# M55M1 register map
File version: 1.0
Registers are 32-bit, read-write, reset 0x0 unless marked. A register's access mark holds for its fields unless they carry their own. Offsets are from the block's base; [hi:lo] are bit positions; {n}, {i} and the like mark numbered series.

## I3Cn — I3C Register Map
Base 0x4029A000
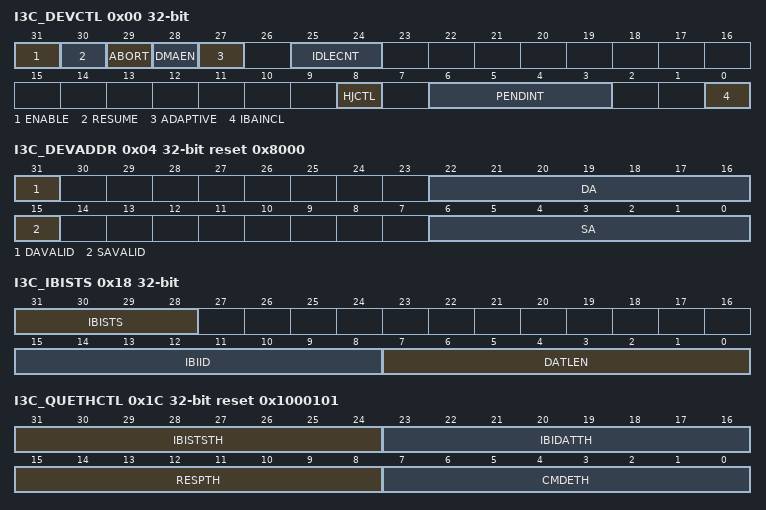
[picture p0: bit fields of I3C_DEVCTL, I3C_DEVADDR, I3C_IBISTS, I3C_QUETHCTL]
0x00 I3C_DEVCTL — I3C Device Control Register
  [31] ENABLE — Controls whether or not I3C is enabled. Note: 1.To Enable the Slave controller, the application must set the ENABLE bit to 1. Enabling the Slave controller might not be instantaneous because it is dependent on the availability of SCL clock on the I3C line. 2.To Disable the Slave controller, the application after setting the value of 0 to the ENABLE bit must keep polling the ENABLE bit to check whether the bit value is zero. Once the ENABLE bit is read with a value of zero, the application can be sure that the Slave controller is disabled. If the SCL clock is present, the Slave controller takes two SCL clocks to come out of the Disable state.
    0=I3C controller Disabled; 1=I3C controller Enabled
  [30] RESUME — I3C Resume Bit. This bit is used to resume the controller after it goes to the halt state. Note: This bit is cleared by writing 1 to it. In the Master mode of operation, the controller goes to the halt state due to any type of error in the transfer. After the controller gones to the halt state, the application has to write 1'b1 to this bit to resume the controller. This bit is auto-cleared once the controller resumes the transfers by initiating the next command. In the Slave mode of operation, the controller goes to the halt state due to following conditions: ■ Any type of error in the transfer ■ MRL Register updated by the master through SETMRL CCC. After the controller goes to the halt state, the application has to take necessary action to handle the error condition and then write 1'b1 to this bit to resume the controller. This bit is auto-cleared once the controller is ready to accept new transfers. (RESUME cannot auto-clear until GETSTATS CCC is received .if Slave has Protocol Error)
    0=RESUME operation is completion; 1=RESUME operation is in progress
  [29] ABORT — Abort Bit. This bit is used in Master mode of operation This bit allows the controller to relinquish the I3C bus before completing the issued transfer In response to an ABORT request, the controller issues the STOP condition after the complete data byte is transferred or received. This bit is auto-cleared once the transfer is aborted and the controller issues a 'Transfer Abort' interrupt.
  [28] DMAEN — DMA Handshake Interface Enable
    0=The DMA handshake control has no significance; 1=Enables the DMA handshake control to interact with external DMA
  [27] ADAPTIVE — Adaptive Mode (effect on HJ operation). This field is used in Slave mode of operation. Setting of this bit is NOT required to put the controller in Adaptive Mode. It is only used to enable some features of the Slave controller to adapt to Adaptive I2C/I3C mode of operation. This bit is cleared automatically if the controller determines the mode as I3C. Effect on Hot- Join: If this bit is programmed to 1'b1, the controller initiates a Hot-Join request only after it has switched to I3C mode of operation. If this bit is not set, the controller initiates a Hot- Join without determining the bus mode assuming itself to be on i3c bus. This bit should be set only if the Slave application does not know to which bus the device is connected to.
  [25:24] IDLECNT — Idle Count Multiplier. This bit is used in Slave mode of operation. After power-on reset, the Slave controller is enabled only after it sees both SDA and SCL lines idle for a specified time. This idle time is calculated by multiplying IDLE_ MUL with AVAILTC field in the I3C_BUSFAT register.
    0=Bus Avaliable time * 1; 1=Bus Avaliable time * 2; 2=Bus Avaliable time * 4; 3=Bus Avaliable time * 8
  [8] HJCTL — Hot-Join ACK/NACK Control. This bit is used in master mode of operation. This bit acts as a global control to ACK/NACK the Hot-Join request from the devices. The I3C Master ACK/NACKs the Hot-Join request from other devices connected on the I3C bus, based on programming of this bit.
    0=ACK the Hot-join request; 1=NACK and send broadcast CCC to disable Hot-Join
  [6:3] PENDINT — Pending Interrupt Status. This field is used in Slave mode of operation. This field is used for setting the interrupt number and is also reflected in I3C_CCCDEVS[3:0] PENDINT.
  [0] IBAINCL — I3C Broadcast Address include. This bit is used in Master mode of operation. This bit is used to include DWC_mipi_i3c broadcast address (0x7E) for private transfer. Note: If I3C broadcast address is not included for the private transfers, In-band Interrupts (IBI) driven from Slaves might not win address arbitration. Hence, the IBIs get delayed.
    0=I3C Broadcast Address is not included for Private Transfer; 1=I3C Broadcast Address is included for Private Transfers
0x04 I3C_DEVADDR reset 0x8000 — I3C Device Address Register
  [31] DAVALID — Dynamic Address Valid. In Master mode, the user sets this bit to 1 as it self-assigns its dynamic address. In I3C Slave Mode the Controller sets this bit to 1 when Main Master assigns the Dynamic address during ENTDAA or SETDASA mechanism. Note: This bit can be auto-clear to 0 if RSTDAA CCC is reveived.
    0=Dynamic Address is invalid; 1=Dynamic Address is valid
  [22:16] DA — Device Dynamic Address. In Master mode, the user/application has to program the Dynamic Address through the Slave interface as it self-assigns its Dynamic Address. In Slave mode, this field is used to indicate the device Dynamic Address after slave completes the dynamic address assignment operation by ENTDAA, SETDASA or SETNEDA CCC. Note: This field is read only.
  [15] SAVALID — Static Address Valid. In slave mode of operation this bit reflects the value of static_addr_en input port. The input port static_addr_en is expected to be driven to 1 only if the device supports I2C or I3C Static Address.
    0=Static Address is invalid; 1=Static Address is valid
  [6:0] SA — Device Static Address. The slave controller uses this address to respond to SETDASA CCC Command to get the Dynamic Address or performs Legacy I2C Read/Write operation.
0x0C I3C_CMDQUE wo — I3C Command Queue Port Register
  [31:0] CMDQUE — Command Queue. Please refer to chapter Master Command Data Structure and chapter Slave Command Data Structure
0x10 I3C_RESPQUE ro — I3C Response Queue Port Register
  [31:0] RESPQUE — Response Queue. Please refer to chapter Master Response Data Structure and chapter Slave Response Data Structure
0x14 I3C_TXRXDAT — I3C Transmit and Receive Data Port Register
  [31:0] DAT — Transmit and Receive Data Port. Transmit (Write) Operation: The Transmit Data port is mapped to the Tx-Data Buffer. The transmit data should always be packed as 4-byte aligned data words and written to the Transmit Data Port register. If the Command length is not aligned to 4-bytes, then the additional bytes are ignored. Receive (Read) Operation: The Receive Data port is mapped to the Rx-Data Buffer. The Receive data is always packed in 4-byte aligned data words and stored in the Rx-Data Buffer. If the command length is not aligned to the 4-bytes, then the additional data bytes have to be ignored.
0x18 I3C_IBIQUE ro — I3C In-Band Interrupt Queue Data Register
  [31:0] IBIDAT — In-Band Interrupt Data. This register is used in master mode of operation. This register when read from, reads the data from the IBI Queue. This register is mapped to the IBI Queue.The IBI Data is always packed in 4-byte aligned and put to the IBI Queue. If the incoming data is not aligned to the 4-bytes, then there are unused bytes in the end location of the IBI transfer
0x18 I3C_IBISTS ro (alternate view of I3C_IBIQUE) — I3C In-Band Interrupt Queue Status Register
  [31:28] IBISTS — I IBI Received Status. Defines the master response for IBI received. 4'b0xxx: Responded with ACK. 4'b1xxx: Responded with NACK. Others: RESERVED
  [15:8] IBIID — IBI Identifier. The byte received after START which includes the address and the R/W bit. Device address and R/W bit in case of Slave Interrupt or Master Request. Hot-Join ID and R/W bit in case of Hot-Join IBI.
  [7:0] DATLEN — In-Band Interrupt data length. This field represents the length of data received along with the IBI, in bytes.
0x1C I3C_QUETHCTL reset 0x1000101 — I3C Queue Threshold Control Register
  [31:24] IBISTSTH — In-Band Interrupt Status Threshold Value. Every In Band Interrupt received by I3C controller generates an IBI status. This field controls the number of IBI status entries (or greater) in the IBI queue that trigger the IBI_THLD_STAT interrupt. The valid range is 0 to IC_IBI_BUF_DEPTH-1. The software programs only valid values. A value of 0 sets the threshold for 1 entry, and a value of N sets the threshold for N+1 entries.
  [23:16] IBIDATTH — IBI Data Threshold Value. This field represents the IBI data segment size in Dwords (4 bytes). The minimum supported segment size is 1 (4 bytes) and the maximum supported size is IC_IBI_DATA_BUF_DEPTH-1. The IBI_DATA_THLD field enables the slicing of the incoming IBI data and generate individual status and thereby promotes the cut-through operation in reading out the IBI data.
  [15:8] RESPTH — Response Buffer Threshold Value. Controls the number of entries (or greater) in the Response. Queue that trigger the RESP_READY_STAT_INTR interrupt. The valid range is 0 to RESP_DT-1. The software programs only valid values. A value of 0 sets the threshold for 1 entry, and a value of N sets the threshold for N+1 entries.
  [7:0] CMDETH — Command Buffer Empty Threshold Value. Controls the number of empty locations (or greater) in the Command Queue that trigger CMD_QUEUE_READY_STAT interrupt. The valid range is 0 to CMD_BUF_DEPTH-1. The software programs only valid values. Value of N ranging from 1 to CMD_BUF_DEPTH-1 sets the threshold to N empty locations and a value of 0 sets the threshold to indicate that the queue is completely empty.
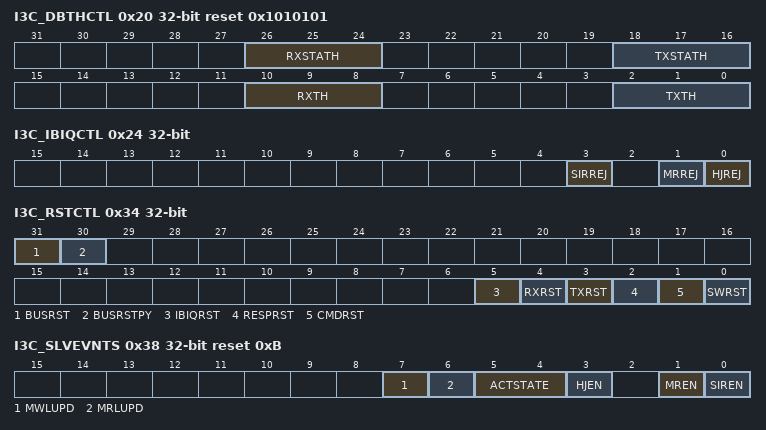
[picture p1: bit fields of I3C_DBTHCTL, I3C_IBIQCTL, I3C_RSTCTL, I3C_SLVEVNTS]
0x20 I3C_DBTHCTL reset 0x1010101 — I3C Data Buffer Threshold Control Register
  [all] fields
    0=1; 1=4; 2=8; 3=16; 4=32
  [26:24] RXSTATH — Receive Start Threshold Value. In master mode of operation when the controller is set up to initiate a read transfer, it waits until either one of the conditions are met before it initiates the read transfer on the I3C Interface. In the slave mode of operation the slave controller ACK's a write request from Master only if threshold number of empty locations(or more) are available in its receive buffer. The supported values for RXSTATH are:
  [18:16] TXSTATH — Transfer Start Threshold Value. In master mode of operation when the controller is set up to initiate a write transfer, it waits until either one of the following conditions are met before it initiates the write transfer on the I3C Interface. In slave mode of operation the slave controller ACK's a read request from Master only if either one of the following conditions are met: 1. Data length (as specified in the command) number of locations are filled in the Transmit FIFO. 2. Threshold number of entries (or more) are available in the Transmit FIFO. The supported values for RXSTATH are:
  [10:8] RXTH — Receive Buffer Threshold Value. The supported values for RXTH are
  [2:0] TXTH — Transmit Buffer Threshold Value. The supported values for TXTH are
0x24 I3C_IBIQCTL — I3C IBI Queue Control Register
  [3] SIRREJ — Notify Rejected Slave Interrupt Request Control. This bit is used to suppress reporting to the application about SIR request rejected. 0x0 : Notify SIR Rejected Disable. 0x1 : Notify SIR Rejected Enable. Note: This register is only used in master mode of operation
  [1] MRREJ — Notify Rejected Master Request Control. This bit is used to suppress reporting to the application about Master request rejected. 0x0 : Notify Master Request Rejected Disable. 0x1 : Notify Master Request Rejected Enable. Note: This register is only used in master mode of operation
  [0] HJREJ — Notify Rejected Master Request Control. This bit is used to suppress reporting to the application about Master request rejected. 0x0 : Notify Master Request Rejected Disable. 0x1 : Notify Master Request Rejected Enable. Note: This register is only used in master mode of operation
0x34 I3C_RSTCTL — I3C Reset Control Register
  [31] BUSRST — Bus Reset. This bit is only used in master mode of operation. Write 1'b1 to this bit to exercise Bus Reset Reset Pattern Generation based on Bus Reset Type selection. This bit is cleared automatically once the Bus Reset Pattern Generation is completed.
  [30] BUSRSTPY — Bus Reset type. Type of bus reset triggered by BUS_RESET field. 2'b00: EXIT: Exit Pattern. 2'b11: SCL_LOW_RESET Pattern
  [5] IBIQRST — IBI Queue Software Reset. This bit is only used in master mode of operation. Write 1'b1 to this bit to exercise IBI Queue reset This bit is cleared automatically once the IBI Queue reset is completed
  [4] RXRST — Receive Buffer Software Reset. Write 1'b1 to this bit to exercise Receive Buffer reset. This bit is cleared automatically once the Receive buffer reset is completed.
  [3] TXRST — Transmit Buffer Software Reset. Write 1'b1 to this bit to exercise Transmit Buffer reset. This bit is cleared automatically once the Transmit Buffer reset is completed.
  [2] RESPRST — Response Queue Software Reset. Write 1'b1 to this bit to exercise Response Queue reset. This bit is cleared automatically once the Response Queue reset is complete.
  [1] CMDRST — Command Queue Software Reset. Write 1'b1 to this bit to exercise Command Queue reset. This bit is cleared automatically once the Command Queue reset is complete.
  [0] SWRST — Core Software Reset. Write 1'b1 to this bit to exercise software reset. This resets all Buffers - Receive, Transmit, Command, and Response. This bit is cleared automatically once the core reset is complete.
0x38 I3C_SLVEVNTS reset 0xB — I3C Slave Event Status Register
  [7] MWLUPD — MWL Updated Status. This bit indicates a SETMWL CCC is received by the slave. The updated MWL value can be read from SLV_MAX_LEN register. This status can be cleared by writing 1'b1 to this field after reading the updated MWL. Note: This bit is cleared by writing 1 to it.
  [6] MRLUPD — MRL Updated Status. This bit indicates a SETMRL CCC is received by the slave. The updated MRL value can be read from SLV_MAX_LEN register. This status can be cleared by writing 1'b1 to this field after reading the updated MRL. Note: This bit is cleared by writing 1 to it.
  [5:4] ACTSTATE — Activity State Status. ENTAS0 - 00. ENTAS1 - 01. ENTAS2 - 10. ENTAS3 - 11. This bit reflects the Activity State of slave set by the Master. Note: This field is read only.
  [3] HJEN — Hot-Join Interrupt Enable Bit. This bit reflects whether the Hot-Join Request Interrupts are allowed on the I3C bus or not. The Slave application can choose to Disable HJ Capability of the SLave Controller (if selected) by setting this field to 0 before 'Enabling' the Controller. When done so, the Slave does not initiate Hot Join and takes part in Address Assignment without initiating Hot Join. If this field is NOT set to 0 by slave application, it can be set or cleared by the I3C Master through ENEC or DISEC CCCs. Once Disabled by software, CCCs do not have any effect on this field. Note: This field is read only.
  [1] MREN — Master Request Enable Bit. In Slave mode of operation, this bit reflects whether the controller can initiate the Master Request on the I3C bus or not.Usually, this bit is set or cleared by the I3C Master throughENEC or DISEC CCC. Note: This bit is read only.
  [0] SIREN — Slave Interrupt Request Enable Bit. In Slave mode of operation, this bit reflects whether the controller can initiate the SIR on the I3C bus or not. Usually, this bit is set or cleared by the I3C Master through ENEC or DISEC CCC. Note: This bit is read only.
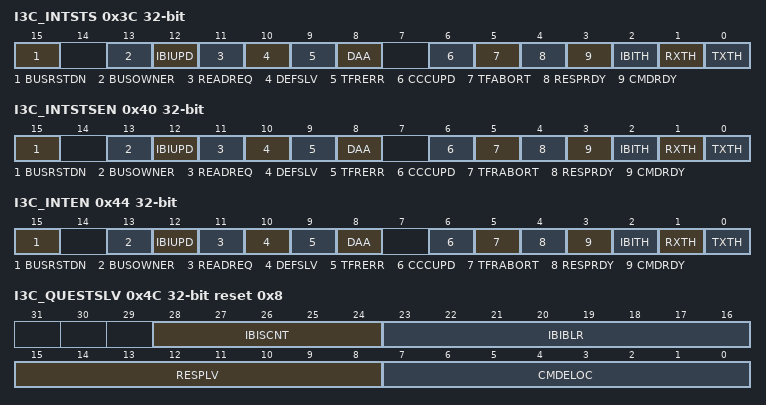
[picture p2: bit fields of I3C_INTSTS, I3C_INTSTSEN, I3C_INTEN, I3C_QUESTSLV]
0x3C I3C_INTSTS — I3C Interrupt Status Register
  [15] BUSRSTDN — Bus Reset Pattern Generation Done Status. This field is used only in Master mode of operation. This interrupt is generated when the SCL Low Timeout Bus Reset Pattern Generation is completed. This bit can be cleared by writing 1'b1.
  [13] BUSOWNER — Bus owner Updated Status. This interrupt is set when the role of the controller changes from being a Master to Slave or vice versa. This bit can be cleared by writing 1'b1.
  [12] IBIUPD — IBI Status Updated. This field is used only in slave mode of operation. It indicates that the IBI request initiated through SIR request register is addressed and status is updated. Note: This bit is cleared by writing 1 to it.
  [11] READREQ — Read Request Received. This field is used only in slave mode of operation. Read Request received from the current master when CMDQ is empty. This bit can be cleared by writing 1'b1. Note: This bit is cleared by writing 1 to it.
  [10] DEFSLV — Define Slave CCC Received Status. This interrupt is generated if DEFSLV CCC is received.This bit can be cleared by writing 1'b1.
  [9] TFRERR — Transfer Error Status. This interrupt is generated if any error occurs during transfer. The error type is specified in the response packet associated with the command (in ERR_STATUS field of RESPONSE_QUEUE_PORT register). This bit can be cleared by writing 1'b1. Note: This bit is cleared by writing 1 to it.
  [8] DAA — Dynamic Address Assigned Status. This field is used only in slave mode of operation. This interrupt is generated if the device's Dynamic Address is assigned through SETDASA or ENTDAA CCC. This bit can be cleared by writing 1'b1. Note: This bit is cleared by writing 1 to it.
  [6] CCCUPD — CCC Table Updated Status. This field is used only in slave mode of operation. This interrupt is generated if any of the CCC registers are updated by I3C Master through CCC commands. This interrupt can be cleared by writing 1'b1. Note: This bit is cleared by writing 1 to it.
  [5] TFABORT — Transfer Abort Status. This field is used only in master mode of operation. This interrupt is generated if transfer is aborted. This interrupt can be cleared by writing 1'b1.
  [4] RESPRDY — Response Queue Ready Status. This interrupt is generated when number of entries in response queue is greater than or equal to threshold value specified by RESPB_TD field in QUETHCTL register. This interrupt is cleared automatically when number of entries in response buffer is less than threshold value specified. Note: This bit is read only.
  [3] CMDRDY — Command Queue Ready Status. This interrupt is generated when number of empty locations in command queue is greater than or equal to threshold value specified by CMDEY_ TD field in QUETHCTL register. This interrupt is cleared automatically when number of empty locations in command buffer is less than threshold value specified. Note: This bit is read only.
  [2] IBITH — IBI Buffer Threshold Status. This field is only used in master mode of operation This interrupt is generated when number of entries in IBI buffer is greater than or equal to threshold value specified by IBISTTH field in I3C_QUETHCTL register. This interrupt is cleared automatically when number of entries in IBI buffer is less than threshold value specified.
  [1] RXTH — Receive Buffer Threshold Status. This interrupt is generated when number of entries in receive buffer is greater than or equal to threshold value specified by RXBUF_TD field in I3C_DBTHCTL register. This interrupt is cleared automatically when number of entries in receive buffer is less than threshold value specified. Note: This bit is read only.
  [0] TXTH — Transmit Buffer Threshold Status. This interrupt is generated when the number of empty locations in transmit buffer is greater than or equal to threshold value specified by TXBUF_TD field in I3C_DBTHCTL register. This interrupt is cleared automatically when number of empty locations in transmit buffer is less than threshold value specified. Note: This bit is read only.
0x40 I3C_INTSTSEN — I3C Interrupt Status Enable Register
  [15] BUSRSTDN — Bus Reset Pattern Generation Done Status Enable Bit. This field is used only in Master mode of operation.
  [13] BUSOWNER — Bus owner Updated Status Enable Bit
  [12] IBIUPD — IBI Updated Status Enable Bit. This field is used in slave mode of operation.
  [11] READREQ — Read Request Received Status Enable Bit. This field is used in slave mode of operation.
  [10] DEFSLV — Define Slave CCC Received Status Enable Bit
  [9] TFRERR — Transfer Error Status Enable Bit
  [8] DAA — Dynamic Address Assigned Status Enable Bit. This field is used in slave mode of operation.
  [6] CCCUPD — CCC Table Updated Status Enable Bit. This field is used in slave mode of operation.
  [5] TFRABORT — Transfer Abort Status Enable Bit. This field is used only in master mode of operation.
  [4] RESPRDY — Response Queue Ready Status Enable Bit
  [3] CMDRDY — Command Queue Ready Status Enable Bit
  [2] IBITH — IBI Buffer Threshold Status Enable Bit
  [1] RXTH — Receive Buffer Threshold Status Enable Bit
  [0] TXTH — Transmit Buffer Threshold Status Enable Bit
0x44 I3C_INTEN — I3C Interrupt Signal Enable Register
  [15] BUSRSTDN — Bus Reset Pattern Generation Done Signal Enable Bit. This field is used only in Master mode of operation.
  [13] BUSOWNER — Bus owner Updated Status Enable Bit
  [12] IBIUPD — IBI Updated Signal Enable Bit. This field is used in slave mode of operation.
  [11] READREQ — Read Request Received Signal Enable Bit. This field is used in slave mode of operation.
  [10] DEFSLV — Define Slave CCC Received Status Enable Bit
  [9] TFRERR — Transfer Error Signal Enable Bit
  [8] DAA — Dynamic Address Assigned Signal Enable Bit. This field is used in slave mode of operation.
  [6] CCCUPD — CCC Table Updated Signal Enable Bit. This field is used in slave mode of operation.
  [5] TFRABORT — Transfer Abort Status Signal Enable Bit. This field is used only in master mode of operation.
  [4] RESPRDY — Response Queue Ready Signal Enable Bit
  [3] CMDRDY — Command Queue Ready Signal Enable Bit
  [2] IBITH — IBI Buffer Threshold Signal Enable Bit
  [1] RXTH — Receive Buffer Threshold Signal Enable Bit
  [0] TXTH — Transmit Buffer Threshold Signal Enable Bit
0x4C I3C_QUESTSLV ro reset 0x8 — I3C Queue Status Level Register
  [28:24] IBISCNT — IBI Buffer Status Count. Contains the number of valid IBI Status entries in the IBI Status Buffer. This field is used in master mode of operation.
  [23:16] IBIBLR — IBI Buffer Level Value. Contains the number of valid IBI Data entries in the IBI Data Buffer. This field is used in master mode of operation
  [15:8] RESPLV — Response Buffer Level Value. Contains the number of valid data entries in the response Buffer.
  [7:0] CMDELOC — Command Queue Empty Locations. Contains the number of empty locations in the command Buffer.
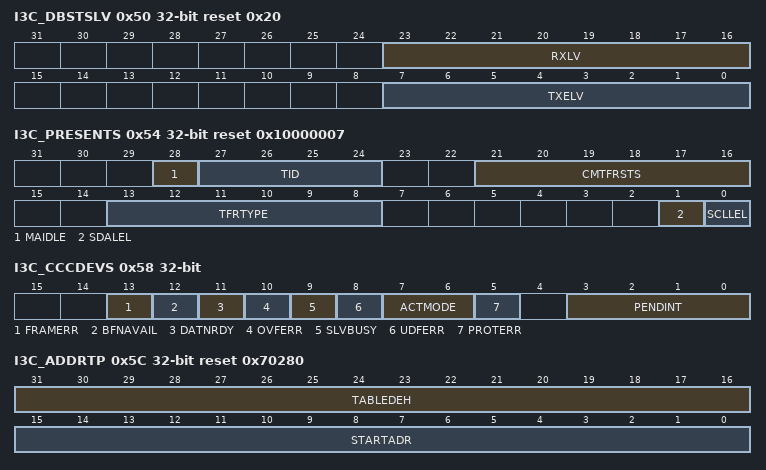
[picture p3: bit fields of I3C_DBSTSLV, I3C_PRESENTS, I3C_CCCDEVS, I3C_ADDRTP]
0x50 I3C_DBSTSLV ro reset 0x20 — I3C Data Buffer Status Level Register
  [23:16] RXLV — Receive Buffer Level Value. Contains the number of valid data entries in the receive Buffer.
  [7:0] TXELV — Transmit Buffer Empty Level Value. Contains the number of empty locations in the transmit Buffer.
0x54 I3C_PRESENTS ro reset 0x10000007 — I3C Present State Register
  [28] MAIDLE — This field reflects whether the Master Controller is in Idle state or not. This bit is set when all the Queues(Command , Response, IBI) and Buffers(Transmit and Receive) are empty along with the Master State machine is in Idle state. 0x0 (MST_NOT_IDLE): Master Controller is not in IDLE State. 0x1 (MST_IDLE): Master Controller is in IDLE State.
  [27:24] TID — Transmit Transaction ID. This field reflects the Transaction ID of the current executing command.
  [21:16] CMTFRSTS — Current Master Transfer State Status Indicates the state of current transfer currently executing by the I3C controller This is valid in Master mode only
  [13:8] TFRTYPE — Transfer Type Status. In Master mode of operation:
    0=IDLE (Controller is in Idle state); 1=Hot-Join transfer state; 2=IBI transfer state; 3=Master write transfer ongoing; 4=Read data prefetch state; 5=Master read transfer ongoing; 6=Slave controller in Halt State waiting for resume from application
  [1] SDALEL — This bit is used to check the SDA line level to recover from errors and for debugging. This bit reflects the value of synchronized sda input signal. This is valid in Master mode only.
  [0] SCLLEL — This bit is used to check the SCL line level to recover from errors and for debugging. This bit reflects the value of synchronized scl input signal. This is valid in Master mode only.
0x58 I3C_CCCDEVS ro — I3C Device Operating Status Register
  [13] FRAMERR — Frame Error. This bit is set when private write request from Master has frame error in HDR-DDR/HDR-TSP/TSL mode. This is cleared only after Master reads the device status through GETSTATUS_CCC.
  [12] BFNAVAIL — Buffer Not Available. This bit is set when private write request from Master is NACKED because of RX buffer not having RX_BUF_THLD number of empty locations or Response buffer is full. In SDR mode of operation this is cleared when the Master issues GET_STATUS CCC or upon space becoming available in the buffer and the successful completion of the next write transfer. In HDR mode of operation it is cleared only when Master issues GET_STATUS CCC
  [11] DATNRDY — Data Not Ready. This bit is set when private read request from Master is NACKED because of any of the following conditions. 1. Command FIFO Empty. 2. Transmit FIFO threshold is not met. 3. Response FIFO Full. This is cleared when the Master issues GET_STATUS CCC or upon successful completion of the subsequent read transfer.
  [10] OVFERR — Overflow Error. Overflow error condition detected during master write transfer. This is cleared only after master reads the Device Status through GETSTATUS CCC.
  [9] SLVBUSY — Slave Busy. This bit is set if any change is made by the current master in to MRL register or occurance of any error. It is cleared after slave application resumes the slave operation by writing 1'b1 in RESUME field of Device Control Register.
  [8] UDFERR — Underflow Error. Under Flow Error during private master read transfer. This bit is set if slave controller terminates a read transfer because of unavailability of data in the transmit buffer. This is cleared only after master reads the Device Status through GETSTATUS CCC.
  [7:6] ACTMODE — Activity Mode. This field reflects the input port signal act_mode.MIPI: Contains the two-bit ID of the Slave Device's current Activity Mode (readiness to support data read of sensor or related information).
  [5] PROTERR — Protocol Error. This bit is set when the slave controller encouters a Parity/CRC error during write data transfer.
  [3:0] PENDINT — Pending Interrupt. This field reflects the value driven on pending_int input port.
0x5C I3C_ADDRTP ro reset 0x70280 — I3C Pointer for Device Address Table Register
  [31:16] TABLEDEH — Depth of Device Address Table
  [15:0] STARTADR — Start Address of Device Address Table.
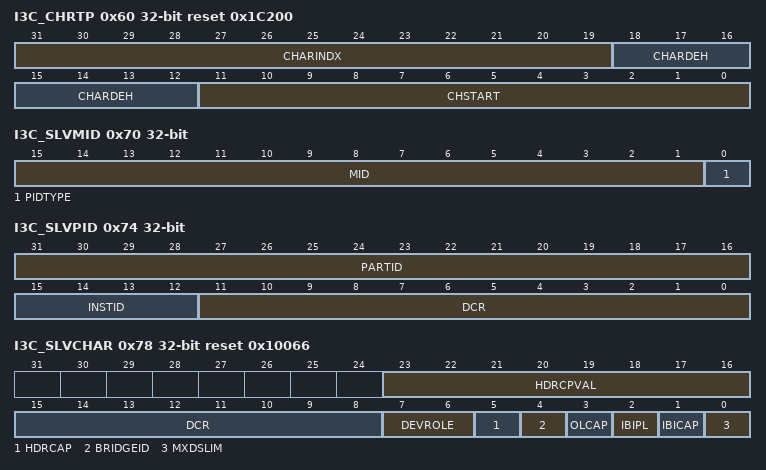
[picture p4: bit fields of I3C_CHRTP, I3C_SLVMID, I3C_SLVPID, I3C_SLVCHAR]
0x60 I3C_CHRTP ro reset 0x1C200 — I3C Pointer for Device Characteristics Table Register
  [31:19] CHARINDX — Current index of Device Characteristics Table This field returns the current location of Device Characteristics Table index Initially, this index points to 0 Once the complete characteristics information of a Slave device is written into Device Characteristics Table during ENTDAA, this index increments by 1 The first winning device information is stored in Device Characteristics Table index 0, the
  [18:12] CHARDEH — Depth of Device Characteristics Table
  [11:0] CHSTART — Start Address of Device Characteristics Table.
0x6C I3C_VENDOR ro reset 0xB0 — I3C Start Address of Vendor specific Register
  [15:0] VENODADR — Pointer for Vendor specific Registers
0x70 I3C_SLVMID — I3C MIPI Manufacturer ID Register
  [15:1] MID — Specifies the MIPI Manufacturer ID (PID[47:33]).
  [0] PIDTYPE — Specifies the Provisional ID Type Selector (PID[32]) (1'b1: Random Value, 1'b0: Vendor Fixed Value)
0x74 I3C_SLVPID — I3C Normal Provisional ID Register
  [31:16] PARTID — Specifies the Part ID of DWC_mipi_i3c device (PID[31:16])
  [15:12] INSTID — This field is used to program the instance ID of the Slave The reset value of this register is taken from input port 'inst_id'.
  [11:0] DCR — Specifies the additional 12-bit ID of DWC_mipi_i3c device (PID[11:0]).
0x78 I3C_SLVCHAR reset 0x10066 — I3C Slave Characteristic Register
  [23:16] HDRCPVAL — I3C Device HDR Capability Register Value. Note: This bit is read only.
    1=HDR-DDR
  [15:8] DCR — I3C Device Characteristic Value
  [7:6] DEVROLE — Device Role field in Bus Characteristic Register (BCR[7:6]). Note: This bit is read only.
  [5] HDRCAP — SDR Only or SDR and HDR Capable field in Bus Characteristic Register (BCR[5])
    0=SDR only. It doesn't disable the HW HDR feature, it just doesn't advertise the Slave HDR capability to Master; 1=HDR capable
  [4] BRIDGEID — Bridge Identifier field in Bus Characteristic Register (BCR[4]). Note: This bit is read only.
    0=Not a bridge device
  [3] OLCAP — Offline Capable field in Bus Characteristic Register (BCR[3]). Note: This bit is read only.
    0=Slave will always respond to I3C bus commands
  [2] IBIPL — IBI Payload field in Bus Characteristic Register (BCR[2]). Note: This bit is read only.
    1=Support IBI payload
  [1] IBICAP — IBI Request Capable field in Bus Characteristic Register (BCR[1]). Note: This bit is read only.
    1=Support IBI
  [0] MXDSLIM — Max Data Speed Limitation field in Bus Characteristic Register (BCR[0])
    0=No limitation; 1=Limitation
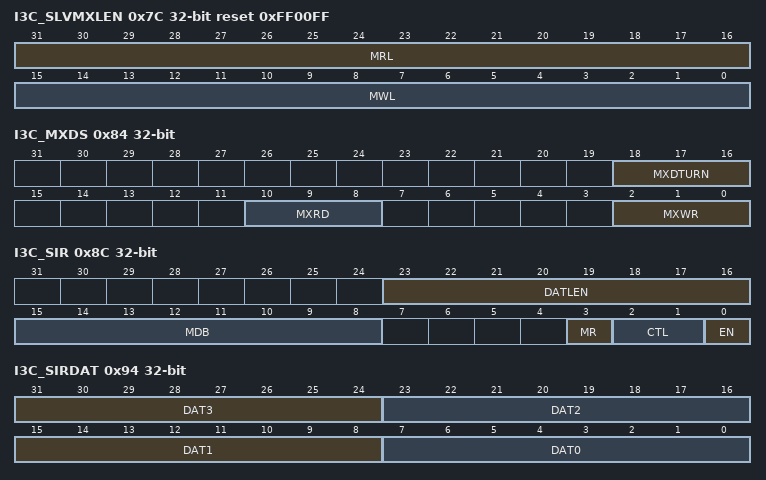
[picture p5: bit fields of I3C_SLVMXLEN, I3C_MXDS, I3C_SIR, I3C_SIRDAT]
0x7C I3C_SLVMXLEN ro reset 0xFF00FF — I3C Maximum Write/Read Length Register
  [31:16] MRL — I3C Device Max Read Length (Can be updated if SETMRL CCC is received)
  [15:0] MWL — I3C Device Max Write Length (Can be updated if SETMWL CCC is received)
0x80 I3C_MXRDTURN ro — I3C Maximum Read Turnaround Time Register
  [23:0] MXRDTURN — Specifies the maximum read turnaround time (in microseconds) (The 3rd byte which returned in the GETMXDS CCC). Note: This field is read only.
0x84 I3C_MXDS — I3C Maximum Data Speed Register
  [18:16] MXDTURN — Specifies the clock to data turnaround time (Tsco parameter)
    {v}={v+8} ns (v=0..4)
  [10:8] MXRD — Specifies the Maximum Sustained Data Rate for non-CCC messages sent by Slave Device to Master Device (The 2nd byte which returned in the GETMXDS CCC)
    0=12.5 MHz; 1=8 MHz; 2=6 MHz; 3=4 MHz; 4=2 MHz
  [2:0] MXWR — Specifies the Maximum Sustained Data Rate for non-CCC messages sent by Master Device to Slave device (The 1st byte which returned in the GETMXDS CCC)
    0=12.5 MHz; 1=8 MHz; 2=6 MHz; 3=4 MHz; 4=2 MHz
0x8C I3C_SIR — I3C Slave Interrupt Request Register
  [23:16] DATLEN — Slave Interrupt Request Data Length. This field should be programmed by the slave application to give the data length for the payload data other than the MDB byte. This field is only applicable when BCR[2] is set indicating that SIR supports payload data.
  [15:8] MDB — Mandatory Data Byte. This field gives the mandatory data byte which is required to be transmitted after the Master ACK the slave address during SIR transfer. This field is only applicable when BCR[2] is set indicating that SIR supports payload data.
  [3] MR — Master Request. When set, the controller attempts to issue the MR on the I3C bus. Once issued and when the current master accepts(ACK) or if the controller is unable to issue the MR, then the controller clears this bit automatically and updates the IBI_STS field. If NACK response is received for the MR, the controller reattempts the MR upon detecting the next START condition from the master or after the Bus Available time. This bit is available only in the secondary master configuration. For other configurations, this bit is reserved and returns 0 when read. Once set, the application cannot clear this bit.
  [2:1] CTL — Slave Interrupt Request Control
    0=Indicates source of SIR data to be from the registers
  [0] EN — Slave Interrupt Request. When set, the slave controller attempts to issue the SIR on the I3C bus. Once issued and when the current master accepts (ACK) or if the controller is unable to issue the SIR, then the controller clears this bit automatically and updates the IBI_STS field. If the NACK response is received for the SIR, the controller reattempts the SIR upon detecting the next START condition from the master or after the Bus Available Time. Once set, the application cannot clear this bit.
0x94 I3C_SIRDAT — I3C Slave Interrupt Request Data Register
  [31:24] DAT3 — SIR Data Byte 3. This register SIRDATA containing four bytes of SIR Data will be in effect only when SIR_CTRL field in INTRREQ is programmed to 00 provided the data length is up to 4. This field holds the fourth byte of SIR DATA that will be passed after the MDB when SIR is initiated by the application on writing into SIR bit in INTRREQ Register.
  [23:16] DAT2 — SIR Data Byte 2. This register SIRDATA containing four bytes of SIR Data will be in effect only when SIR_CTRL field in INTRREQ is programmed to 00 provided the data length is up to 3. This field holds the third byte of SIR DATA that will be passed after the MDB when SIR is initiated by the application on writing into SIR bit in INTRREQ Register.
  [15:8] DAT1 — SIR Data Byte 1. This register SIRDATA containing four bytes of SIR Data will be in effect only when SIR_CTRL field in INTRREQ is programmed to 00 provided the data length is up to 2. This field holds the second byte of SIR DATA that will be passed after the MDB when SIR is initiated by the application on writing into SIR bit in INTRREQ Register.
  [7:0] DAT0 — SIR Data Byte 0. This register SIRDATA containing four bytes of SIR Data will be in effect only when SIR_CTRL field in INTRREQ is programmed to 00 provided the data length is up to 1. This field holds the first byte of SIR DATA that will be passed after the MDB when SIR is initiated by the application on writing into SIR bit in INTRREQ Register.
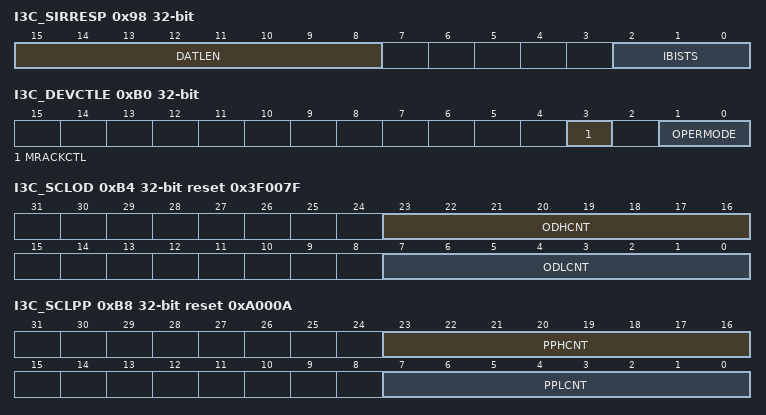
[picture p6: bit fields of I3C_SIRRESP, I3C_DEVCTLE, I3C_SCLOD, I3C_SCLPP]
0x98 I3C_SIRRESP — I3C Slave Interrupt Request Response Register
  [15:8] DATLEN — Data Length for SIR Response. The value in this filed will indicate the number of bytes remaining that was not transmitted because of Master early terminating the SIR transfer. In case the IBI is not attempted the number for bytes returned will be same as that programmed for IBI payload
  [2:0] IBISTS — IBI Completion Status. This field is common for SIR and MR. The controller does not attempt to issue the IBI and generates the IBI Completion Status as 3'b011 if one of the following condition is true. 1. Master has not assigned the Dynamic Address. 2. Master has cleared the assigned Dynamic Address (through RSTDAA CCC). 3. Master has disabled the IBI event (through DISEC CCC). 4. The controller has switched the role to Master (applicable only for secondary master configuration). 5. DL doesn't match with SIR_CTRL.
    1=IBI accepted by the Master (ACK response received); 2=Master Early Terminate (only for SIR with Data); 3=IBI Not Attempted
0xB0 I3C_DEVCTLE — I3C Device Control Extended Register
  [3] MRACKCTL — In Slave mode of operation, this bit serves as a control to ACK/NACK GETACCMST CCC from current master. 0: ACK GETACCMST CCC. 1: NACK GETACCMST CCC
  [1:0] OPERMODE — This bit is used to select the Device Operation Mode before the controller is enabled. 0: Master. 1: Slave. 2: Reserved. 3: Reserved. Note:This field is written only when the i3c is disabled
0xB4 I3C_SCLOD reset 0x3F007F — I3C SCL Open Drain Timing Register
  [23:16] ODHCNT — I3C Open Drain High Count. SCL open-drain High count for I3C transfers targeted to I3C devices. Note: ODHCNT minimum value is five
  [7:0] ODLCNT — I3C Open Drain Low Count. SCL Open-drain low count for I3C transfers targeted to I3C devices. Note: ODLCNT minimum value is five
0xB8 I3C_SCLPP reset 0xA000A — I3C SCL Push Pull Timing Register
  [23:16] PPHCNT — I3C Push Pull High Count. SCL Push-Pull High count for I3C transfers targeted to I3C devices. Note: PPHCNT minimum value is five
  [7:0] PPLCNT — I3C Push Pull Low Count. SCL Push-Pull low count for I3C transfers targeted to I3C devices. Note: PPLCNT minimum value is five
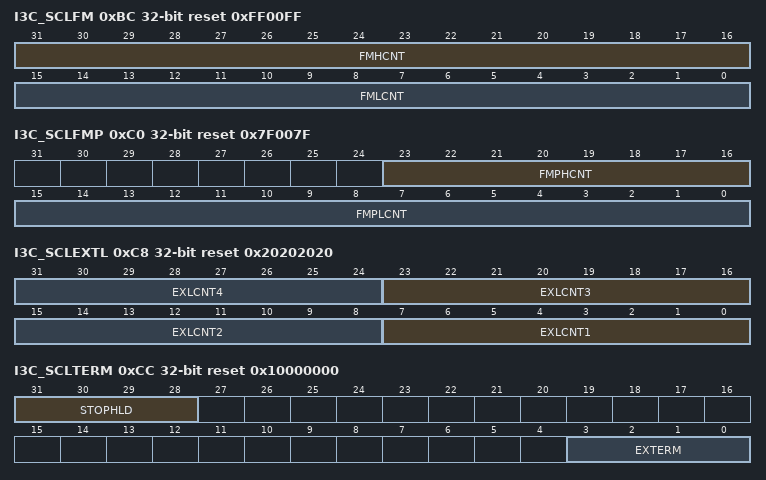
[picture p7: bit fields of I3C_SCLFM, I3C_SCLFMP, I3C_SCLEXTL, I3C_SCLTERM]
0xBC I3C_SCLFM reset 0xFF00FF — I3C SCL I2C Fast Mode Timing Register
  [31:16] FMHCNT — I2C Fast Mode High Count. The SCL open-drain high count timing for I2C fast mode transfers. Note: FMHCNT minimum value is five
  [15:0] FMLCNT — I2C Fast Mode Low Count. The SCL open-drain low count timing for I2C fast mode transfers. Note: FMLCNT minimum value is five
0xC0 I3C_SCLFMP reset 0x7F007F — I3C SCL I2C Fast Mode Plus Timing Register
  [23:16] FMPHCNT — I2C Fast Mode High Count. The SCL open-drain high count timing for I2C fast mode transfers. Note: FMPHCNT minimum value is five
  [15:0] FMPLCNT — I2C Fast Mode Low Count. The SCL open-drain low count timing for I2C fast mode transfers. Note: FMPLCNT minimum value is five
0xC8 I3C_SCLEXTL reset 0x20202020 — I3C SCL Extended Low Count Timing Register
  [8n-1:8n-8] EXLCNT{n} (n=1..4) — I3C Extended Low Count Register {n}. SDR{n} uses this register field for data transfer
0xCC I3C_SCLTERM reset 0x10000000 — I3C SCL Termination Bit Low count Timing Register
  [31:28] STOPHLD — STOP HOLD Count. Stop Hold Count in terms of ECLK which is used for generation of Stop Hold generation in Controller Mode.
  [3:0] EXTERM — I3C Read Termination Bit Low count. Extended I3C Read Termination Bit low count for I3C Readtransfers. Effective Termination-Bit Low Period is derived based on the SDR speed as shown below SDR0 speed: PPLCNT + EXTERM. SDR1 speed: EXLCNT1 + EXTERM. SDR2 speed: EXLCNT2 + EXTERM. SDR3 speed: EXLCNT3 + EXTERM. SDR4 speed: EXLCNT4 + EXTERM
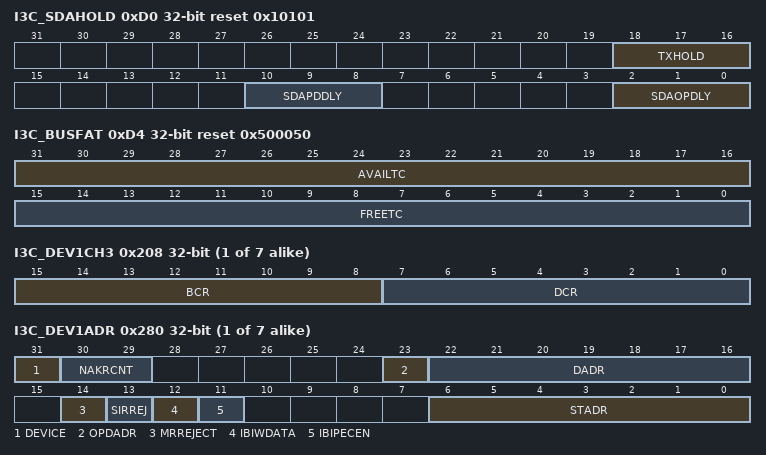
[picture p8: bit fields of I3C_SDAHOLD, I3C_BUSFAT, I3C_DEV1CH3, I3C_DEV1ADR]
0xD0 I3C_SDAHOLD reset 0x10101 — I3C SDA Hold and Mode Switch Delay Timing Register
  [18:16] TXHOLD — TX Hold time. This field controls the hold time (in term of the core clock period) of the transmit data (SDA) with respect to the SCL edge in FM FM+ SDR and DDR speed mode of operations. The valid values are 1 to 7. Others are Reserved.
  [10:8] SDAPDDLY — PD Mode SDA Delay
  [2:0] SDAOPDLY — OP Mode SDA Delay
0xD4 I3C_BUSFAT reset 0x500050 — I3C Bus Free and Available Timing Register
  [31:16] AVAILTC — Bus Avaliable Time Count Value. This register field is used only in Slave mode of operation Bus Available Count Value . This field is used by the Slave to initiate an IBI after STOP condition. (for IBI)
  [15:0] FREETC — Bus Free Time Count Value. This register field is used only in Master mode of operation I3C Bus Free Count Value. In Pure Bus System, this field represents tCAS parameter. In Mixed Bus system, this field is expected to be programmed to tLOW of I2C Timing
0xD8 I3C_BUSIDLET reset 0x50 — I3C Bus Idle Timing Register
  [19:0] IDLETC — Bus Idle Time Count Value. This field is used by the controller in Slave mode to initiate Hot-Join request if the dynamic address is not valid. (for Hot-Join)
0xDC I3C_SCLLOW reset 0x500000 — I3C SCL Low Timeout register
  [25:0] LOWTIMER — This count defines the number of core clock periods to count for generation of the SCL Low Bus Reset Pattern.
{0x1F0+0x10*i} I3C_DEV{i}CH1 ro reset not defined (i=1..7) — Device Characteristic Table Location-1 of Device{i} register
  [31:0] PIDMSB — The LSB 32-bit value of Provisional-ID
{0x1F4+0x10*i} I3C_DEV{i}CH2 ro reset not defined (i=1..7) — Device Characteristic Table Location-2 of Device{i} register
  [15:0] PIDLSB — The MSB 16-bit value of Provisional-ID
{0x1F8+0x10*i} I3C_DEV{i}CH3 ro reset not defined (i=1..7) — Device Characteristic Table Location-3 of Device{i} register
  [15:8] BCR — Bus Characteristic Value
  [7:0] DCR — Device Characteristic Value
{0x1FC+0x10*i} I3C_DEV{i}CH4 ro reset not defined (i=1..7) — Device Characteristic Table Location-4 of Device{i} register
  [7:0] DADR — Device Dynamic Address assigned.
{0x27C+4i} I3C_DEV{i}ADR reset not defined (i=1..7) — Device Address Table Location of Device{i}
  [31] DEVICE — Type of device. 0: I3C. 1: I2C
  [30:29] NAKRCNT — This field is used to set the Device NACK Retry count for the particular device. If the Device NACK's for the device address, the controller automatically retries the same device until this count expires. If the Slave does not ACK for the mentioned number of retries, then Controller generates an error response and move to the Halt state. This feature is used for Retry Model for the following features mentioned in the I3C Specification: Retry Model for Direct GET CCC Commands. The incoming SIR-IBI matches with the slave address initated by the Master
  [23] OPDADR — Odd parity of the 7-bit Dynamic address. Odd parity of the 7-bit Dynamic address used for ENTDAA address assignment
  [22:16] DADR — Device Dynamic Address with parity. This field consists of Dynamic address and Parity Bit. The LSB bits [22:16] should consist of Dynamic Address field indicates the address to be assigned for the winning I3C device when using ENTDAA command.
  [14] MRREJECT — In-Band Master Request Reject field is used to control, per device, whether to accept Master request from Devices. 0x0: Accept: ACK the Master Request. 0x1: Reject: NACK the Master Request and send auto disable CCC.
  [13] SIRREJ — In-Band Slave Interrupt Request Reject field is used to control, per device, whether to accept Slave Interrupt request from Devices. 0x0 : Accept: ACK the SIR. 0x1 :Reject: NACK the SIR and send auto disable CCC.
  [12] IBIWDATA — Mandatory one or more data bytes follow the accepted IBI from the device Data byte continuation is indicated by T-Bit. 0x0 : IBI Without Mandatory Byte. 0x1 : IBI with one or more Mandatory Bytes
  [11] IBIPECEN — Packet Error Check enabled for accepted IBI from the device PEC byte is appended at the end of IBI data from the device This bit controls whether PEC check should be performed for IBI data from device This bit also controls whether PEC byte has to be send for auto disable CCC when controller NACKs the IBI. 0x0 : Packet Error Check disabled for IBI. 0x1 : Packet Error Check enabled for IBI
  [6:0] STADR — Device Static Address.
